# BL808 register map
Vendor: Bouffalo Lab; File version: 0.1
Registers are 32-bit, read-write, reset 0x0 unless marked. A register's access mark holds for its fields unless they carry their own. Offsets are from the block's base; [hi:lo] are bit positions; {n}, {i} and the like mark numbered series.

## CCI — Camera Control Interface
Base 0x20008000
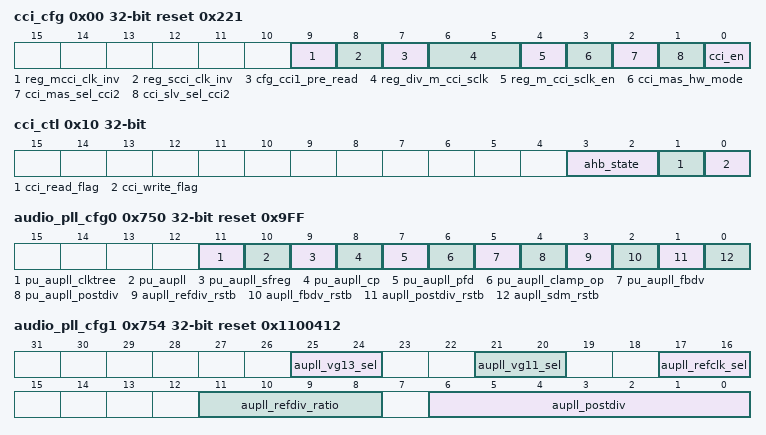
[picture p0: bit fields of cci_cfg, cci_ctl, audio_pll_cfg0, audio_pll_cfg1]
0x00 cci_cfg reset 0x221
  [9] reg_mcci_clk_inv, [8] reg_scci_clk_inv, [7] cfg_cci1_pre_read, [6:5] reg_div_m_cci_sclk, [4] reg_m_cci_sclk_en, [3] cci_mas_hw_mode, [2] cci_mas_sel_cci2, [1] cci_slv_sel_cci2, [0] cci_en
0x04 cci_addr
  [31:0] apb_cci_addr
0x08 cci_wdata
  [31:0] apb_cci_wdata
0x0C cci_rdata
  [31:0] apb_cci_rdata ro
0x10 cci_ctl
  [3:2] ahb_state ro, [1] cci_read_flag ro, [0] cci_write_flag ro
0x750 audio_pll_cfg0 reset 0x9FF
  [11] pu_aupll_clktree, [10] pu_aupll, [9] pu_aupll_sfreg, [8] pu_aupll_cp, [7] pu_aupll_pfd, [6] pu_aupll_clamp_op, [5] pu_aupll_fbdv, [4] pu_aupll_postdiv, [3] aupll_refdiv_rstb, [2] aupll_fbdv_rstb, [1] aupll_postdiv_rstb, [0] aupll_sdm_rstb
0x754 audio_pll_cfg1 reset 0x1100412
  [25:24] aupll_vg13_sel, [21:20] aupll_vg11_sel, [17:16] aupll_refclk_sel, [11:8] aupll_refdiv_ratio, [6:0] aupll_postdiv
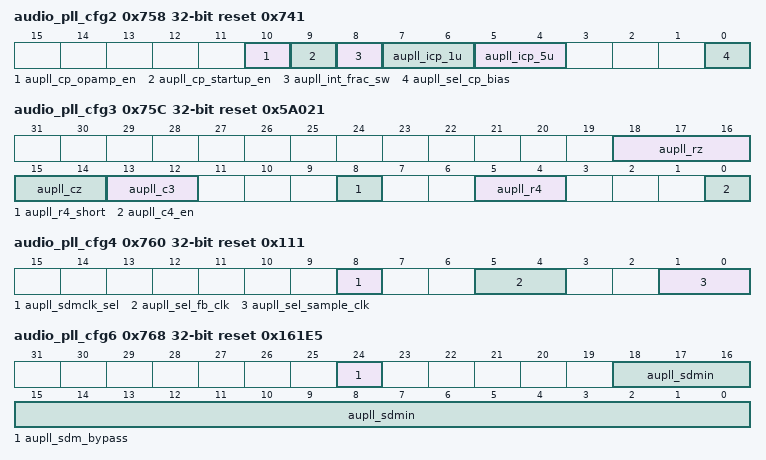
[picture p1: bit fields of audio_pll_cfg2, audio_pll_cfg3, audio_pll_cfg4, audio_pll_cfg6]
0x758 audio_pll_cfg2 reset 0x741
  [10] aupll_cp_opamp_en, [9] aupll_cp_startup_en, [8] aupll_int_frac_sw, [7:6] aupll_icp_1u, [5:4] aupll_icp_5u, [0] aupll_sel_cp_bias
0x75C audio_pll_cfg3 reset 0x5A021
  [18:16] aupll_rz, [15:14] aupll_cz, [13:12] aupll_c3, [8] aupll_r4_short, [5:4] aupll_r4, [0] aupll_c4_en
0x760 audio_pll_cfg4 reset 0x111
  [8] aupll_sdmclk_sel, [5:4] aupll_sel_fb_clk, [1:0] aupll_sel_sample_clk
0x764 audio_pll_cfg5 reset 0x3
  [2:0] aupll_vco_speed
0x768 audio_pll_cfg6 reset 0x161E5
  [24] aupll_sdm_bypass, [18:0] aupll_sdmin
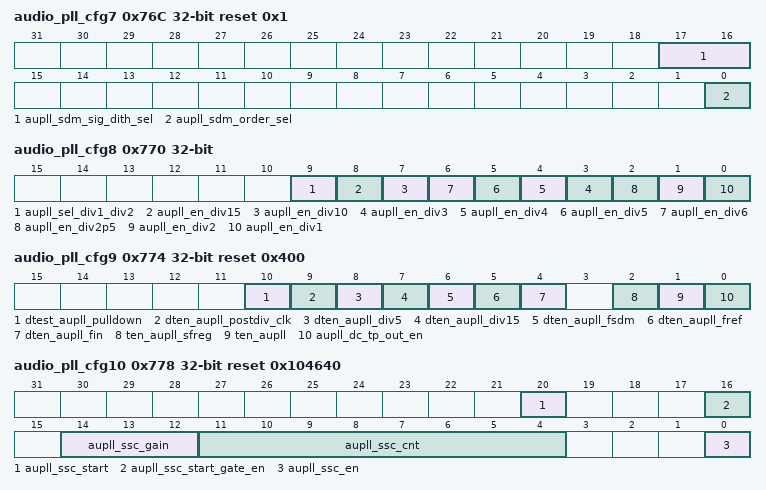
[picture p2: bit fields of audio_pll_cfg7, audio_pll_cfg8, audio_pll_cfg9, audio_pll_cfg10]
0x76C audio_pll_cfg7 reset 0x1
  [17:16] aupll_sdm_sig_dith_sel, [0] aupll_sdm_order_sel
0x770 audio_pll_cfg8
  [9] aupll_sel_div1_div2, [8] aupll_en_div15, [7] aupll_en_div10, [n] aupll_en_div{n} (n=3..6), [2] aupll_en_div2p5, [1] aupll_en_div2, [0] aupll_en_div1
0x774 audio_pll_cfg9 reset 0x400
  [10] dtest_aupll_pulldown, [9] dten_aupll_postdiv_clk, [8] dten_aupll_div5, [7] dten_aupll_div15, [6] dten_aupll_fsdm, [5] dten_aupll_fref, [4] dten_aupll_fin, [2] ten_aupll_sfreg, [1] ten_aupll, [0] aupll_dc_tp_out_en
0x778 audio_pll_cfg10 reset 0x104640
  [20] aupll_ssc_start, [16] aupll_ssc_start_gate_en, [14:12] aupll_ssc_gain, [11:4] aupll_ssc_cnt, [0] aupll_ssc_en
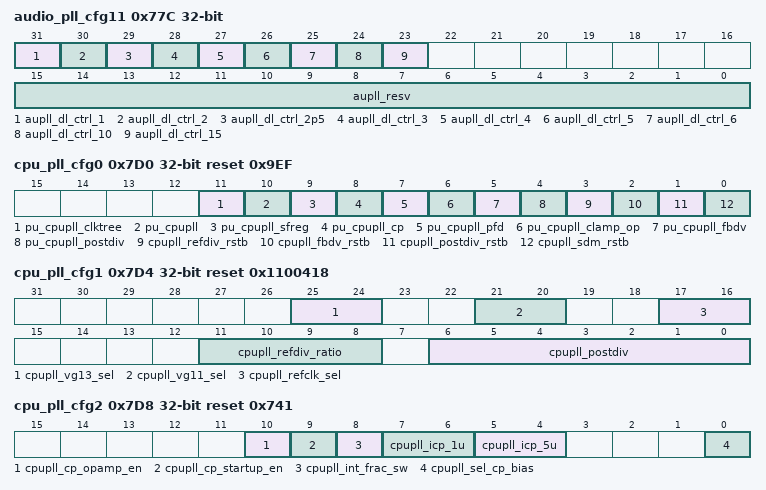
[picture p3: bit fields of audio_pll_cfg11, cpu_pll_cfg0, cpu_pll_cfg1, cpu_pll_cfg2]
0x77C audio_pll_cfg11
  [31] aupll_dl_ctrl_1, [30] aupll_dl_ctrl_2, [29] aupll_dl_ctrl_2p5, [31-n] aupll_dl_ctrl_{n} (n=3..6), [24] aupll_dl_ctrl_10, [23] aupll_dl_ctrl_15, [15:0] aupll_resv
0x7D0 cpu_pll_cfg0 reset 0x9EF
  [11] pu_cpupll_clktree, [10] pu_cpupll, [9] pu_cpupll_sfreg, [8] pu_cpupll_cp, [7] pu_cpupll_pfd, [6] pu_cpupll_clamp_op, [5] pu_cpupll_fbdv, [4] pu_cpupll_postdiv, [3] cpupll_refdiv_rstb, [2] cpupll_fbdv_rstb, [1] cpupll_postdiv_rstb, [0] cpupll_sdm_rstb
0x7D4 cpu_pll_cfg1 reset 0x1100418
  [25:24] cpupll_vg13_sel, [21:20] cpupll_vg11_sel, [17:16] cpupll_refclk_sel, [11:8] cpupll_refdiv_ratio, [6:0] cpupll_postdiv
0x7D8 cpu_pll_cfg2 reset 0x741
  [10] cpupll_cp_opamp_en, [9] cpupll_cp_startup_en, [8] cpupll_int_frac_sw, [7:6] cpupll_icp_1u, [5:4] cpupll_icp_5u, [0] cpupll_sel_cp_bias
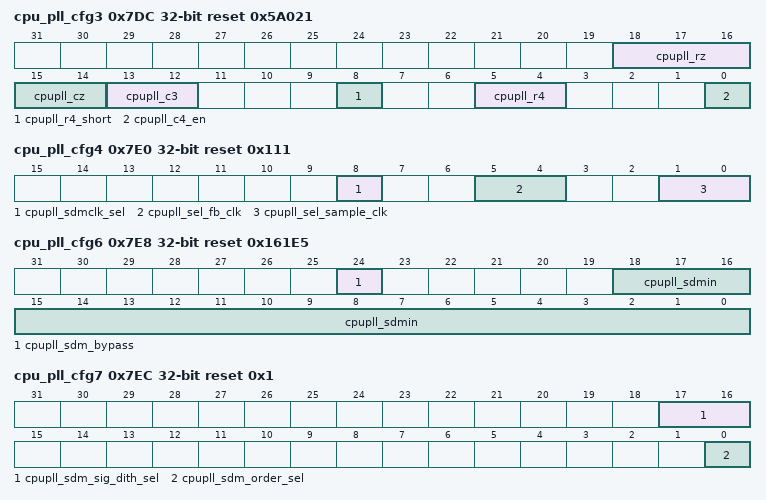
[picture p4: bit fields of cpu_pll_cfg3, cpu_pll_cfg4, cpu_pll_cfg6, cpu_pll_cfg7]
0x7DC cpu_pll_cfg3 reset 0x5A021
  [18:16] cpupll_rz, [15:14] cpupll_cz, [13:12] cpupll_c3, [8] cpupll_r4_short, [5:4] cpupll_r4, [0] cpupll_c4_en
0x7E0 cpu_pll_cfg4 reset 0x111
  [8] cpupll_sdmclk_sel, [5:4] cpupll_sel_fb_clk, [1:0] cpupll_sel_sample_clk
0x7E4 cpu_pll_cfg5 reset 0x3
  [2:0] cpupll_vco_speed
0x7E8 cpu_pll_cfg6 reset 0x161E5
  [24] cpupll_sdm_bypass, [18:0] cpupll_sdmin
0x7EC cpu_pll_cfg7 reset 0x1
  [17:16] cpupll_sdm_sig_dith_sel, [0] cpupll_sdm_order_sel
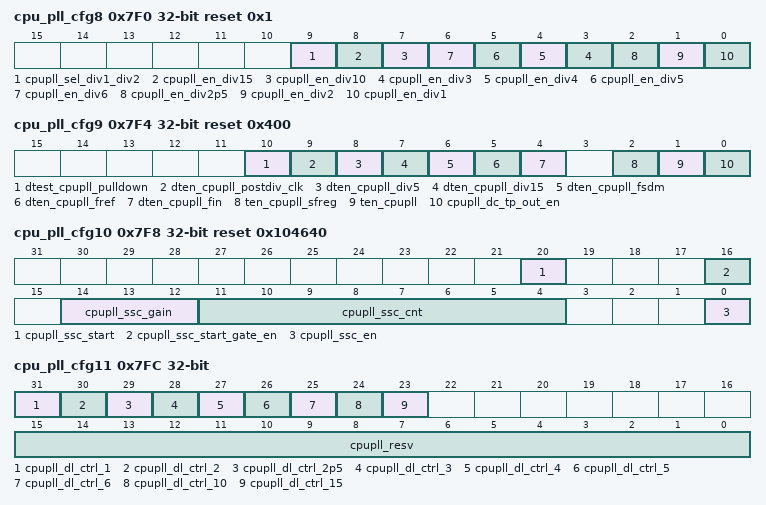
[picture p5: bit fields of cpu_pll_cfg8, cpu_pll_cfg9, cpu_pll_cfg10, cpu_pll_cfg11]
0x7F0 cpu_pll_cfg8 reset 0x1
  [9] cpupll_sel_div1_div2, [8] cpupll_en_div15, [7] cpupll_en_div10, [n] cpupll_en_div{n} (n=3..6), [2] cpupll_en_div2p5, [1] cpupll_en_div2, [0] cpupll_en_div1
0x7F4 cpu_pll_cfg9 reset 0x400
  [10] dtest_cpupll_pulldown, [9] dten_cpupll_postdiv_clk, [8] dten_cpupll_div5, [7] dten_cpupll_div15, [6] dten_cpupll_fsdm, [5] dten_cpupll_fref, [4] dten_cpupll_fin, [2] ten_cpupll_sfreg, [1] ten_cpupll, [0] cpupll_dc_tp_out_en
0x7F8 cpu_pll_cfg10 reset 0x104640
  [20] cpupll_ssc_start, [16] cpupll_ssc_start_gate_en, [14:12] cpupll_ssc_gain, [11:4] cpupll_ssc_cnt, [0] cpupll_ssc_en
0x7FC cpu_pll_cfg11
  [31] cpupll_dl_ctrl_1, [30] cpupll_dl_ctrl_2, [29] cpupll_dl_ctrl_2p5, [31-n] cpupll_dl_ctrl_{n} (n=3..6), [24] cpupll_dl_ctrl_10, [23] cpupll_dl_ctrl_15, [15:0] cpupll_resv

## IPC — Inter-processor Channel
Base 0x2000A800
0x00 cpu1_ipc_iswr — Interrupt Set Write Register
  [15:0] cpu1_ipc_iswr wo
0x04 cpu1_ipc_irsrr — Interrupt raw status Register
  [15:0] cpu1_ipc_irsrr ro
0x08 cpu1_ipc_icr — Interrupt Clear Register
  [15:0] cpu1_ipc_icr wo
0x0C cpu1_ipc_iusr — Interrupt Unmask Set Register
  [15:0] cpu1_ipc_iusr ro
0x10 cpu1_ipc_iucr — Interrupt Unmask Clear Register
  [15:0] cpu1_ipc_iucr wo
0x14 cpu1_ipc_ilslr — Interrupt Line Sel Low Register
0x18 cpu1_ipc_ilshr — Interrupt Line Sel High Register
0x1C cpu1_ipc_isr — Interrupt status Register
  [15:0] cpu1_ipc_isr ro
0x20 cpu0_ipc_iswr — Interrupt Set Write Register
  [15:0] cpu0_ipc_iswr wo
0x24 cpu0_ipc_irsrr — Interrupt raw status Register
  [15:0] cpu0_ipc_irsrr ro
0x28 cpu0_ipc_icr — Interrupt Clear Register
  [15:0] cpu0_ipc_icr wo
0x2C cpu0_ipc_iusr — Interrupt Unmask Set Register
  [15:0] cpu0_ipc_iusr ro
0x30 cpu0_ipc_iucr — Interrupt Unmask Clear Register
  [15:0] cpu0_ipc_iucr ro
0x34 cpu0_ipc_ilslr — Interrupt Line Sel Low Register
0x38 cpu0_ipc_ilshr — Interrupt Line Sel High Register
0x3C cpu0_ipc_isr — Interrupt status Register
  [15:0] cpu0_ipc_isr ro

## MISC — Chip Miscellaneous control
Base 0x20009000
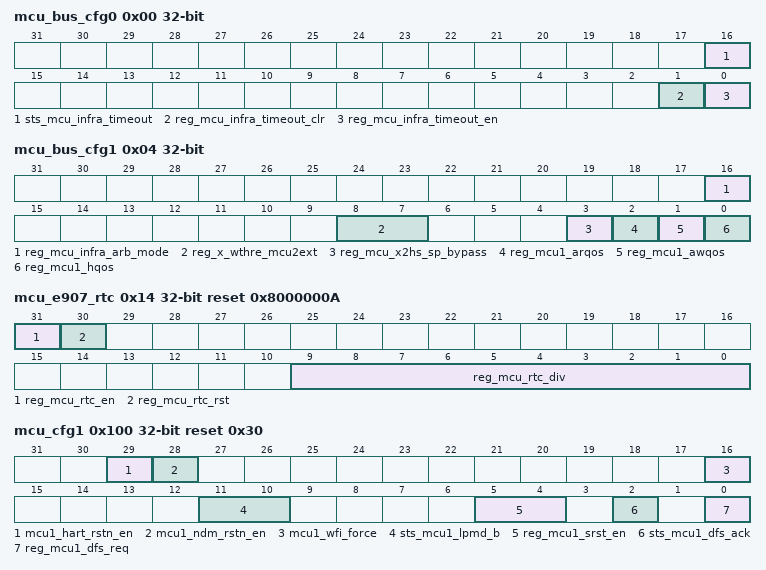
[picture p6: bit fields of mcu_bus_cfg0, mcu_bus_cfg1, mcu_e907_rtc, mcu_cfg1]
0x00 mcu_bus_cfg0
  [16] sts_mcu_infra_timeout ro, [1] reg_mcu_infra_timeout_clr, [0] reg_mcu_infra_timeout_en
0x04 mcu_bus_cfg1
  [16] reg_mcu_infra_arb_mode, [8:7] reg_x_wthre_mcu2ext, [3] reg_mcu_x2hs_sp_bypass, [2] reg_mcu1_arqos, [1] reg_mcu1_awqos, [0] reg_mcu1_hqos
0x14 mcu_e907_rtc reset 0x8000000A
  [31] reg_mcu_rtc_en, [30] reg_mcu_rtc_rst, [9:0] reg_mcu_rtc_div
0x100 mcu_cfg1 reset 0x30
  [29] mcu1_hart_rstn_en, [28] mcu1_ndm_rstn_en, [16] mcu1_wfi_force, [11:10] sts_mcu1_lpmd_b ro, [5:4] reg_mcu1_srst_en, [2] sts_mcu1_dfs_ack ro, [0] reg_mcu1_dfs_req
0x110 mcu1_log1
  [31:0] sts_mcu1_mcause ro
0x114 mcu1_log2
  [31:0] sts_mcu1_mintstatus ro
0x118 mcu1_log3
  [31:0] sts_mcu1_mstatus ro
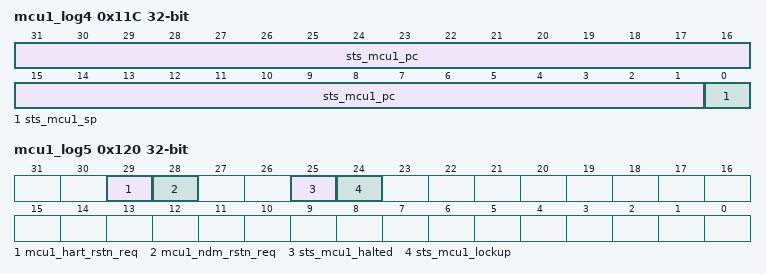
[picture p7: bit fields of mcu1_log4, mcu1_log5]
0x11C mcu1_log4
  [31:1] sts_mcu1_pc ro, [0] sts_mcu1_sp ro
0x120 mcu1_log5
  [29] mcu1_hart_rstn_req ro, [28] mcu1_ndm_rstn_req ro, [25] sts_mcu1_halted ro, [24] sts_mcu1_lockup ro
0x208 irom1_misr_dataout_0
0x20C irom1_misr_dataout_1
